AUTOSAR XML (schema 314)
package /ComponentType
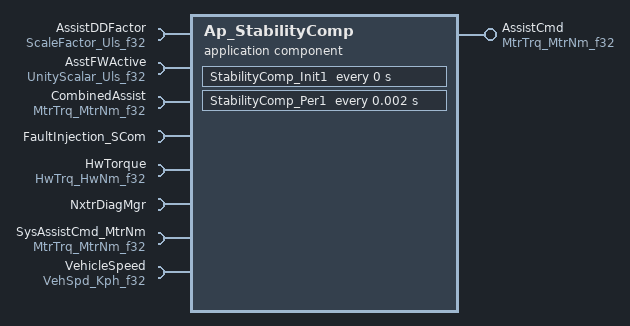
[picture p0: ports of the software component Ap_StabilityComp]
  application software component type Ap_StabilityComp
    provide port AssistCmd: unqueued-sender-com-spec{data-element=MtrNm_f32, can-invalidate=false, init-value=D_ZERO_ULS_F32}, provided-interface=MtrTrq_MtrNm_f32
    8 x require port:
      AssistDDFactor: unqueued-receiver-com-spec{data-element=Uls_f32, init-value=D_ONE_ULS_F32}, required-interface=ScaleFactor_Uls_f32
      AsstFWActive: unqueued-receiver-com-spec{data-element=Uls_f32, init-value=D_ZERO_ULS_F32}, required-interface=UnityScalar_Uls_f32
      CombinedAssist: unqueued-receiver-com-spec{data-element=MtrNm_f32, init-value=D_ZERO_ULS_F32}, required-interface=MtrTrq_MtrNm_f32
      FaultInjection_SCom: client-com-spec=FltInjection, required-interface=FaultInjection_SCom
      HwTorque: unqueued-receiver-com-spec{data-element=HwNm_f32, init-value=D_ZERO_ULS_F32}, required-interface=HwTrq_HwNm_f32
      NxtrDiagMgr: required-com-specs=[GetNTCActive, GetNTCFailed, GetNTCStatus, SetNTCStatus], required-interface=NxtrDiagMgr
      SysAssistCmd_MtrNm: unqueued-receiver-com-spec{data-element=MtrNm_f32, init-value=D_ZERO_ULS_F32}, required-interface=MtrTrq_MtrNm_f32
      VehicleSpeed: unqueued-receiver-com-spec{data-element=Kph_f32, init-value=D_ZERO_ULS_F32}, required-interface=VehSpd_Kph_f32
  internal behavior Ap_StabilityComp_InternalBehavior: component=Ap_StabilityComp
    timing event StabilityComp_Init1_InitEvent: start-on-event=StabilityComp_Init1, period=0
    timing event TMT_StabilityComp_Per1: start-on-event=StabilityComp_Per1, period=0.002
    port-api-options:
      enable-take-address=false, indirect-api=false, port=AssistCmd
      enable-take-address=false, indirect-api=false, port=AssistDDFactor
      enable-take-address=false, indirect-api=false, port=AsstFWActive
      enable-take-address=false, indirect-api=false, port=CombinedAssist
      enable-take-address=false, indirect-api=false, port=FaultInjection_SCom
      enable-take-address=false, indirect-api=false, port=HwTorque
      enable-take-address=false, indirect-api=false, port=NxtrDiagMgr
      enable-take-address=false, indirect-api=false, port=SysAssistCmd_MtrNm
      enable-take-address=false, indirect-api=false, port=VehicleSpeed
    runnable StabilityComp_Init1
    runnable StabilityComp_Per1
      6 x data read access:
        READ_AssistDDFactor_Uls_f32: data-element=AssistDDFactor.Uls_f32
        READ_AsstFWActive_Uls_f32: data-element=AsstFWActive.Uls_f32
        READ_CombinedAssist_MtrNm_f32: data-element=CombinedAssist.MtrNm_f32
        READ_HwTorque_HwNm_f32: data-element=HwTorque.HwNm_f32
        READ_SysAssistCmd_MtrNm_MtrNm_f32: data-element=SysAssistCmd_MtrNm.MtrNm_f32
        READ_VehicleSpeed_Kph_f32: data-element=VehicleSpeed.Kph_f32
      data write access WRITE_AssistCmd_MtrNm_f32: data-element=AssistCmd.MtrNm_f32
      sync call SC_FaultInjection_SCom_FltInjection: operation=FaultInjection_SCom.FltInjection, timeout=0
      sync call SC_NxtrDiagMgr_SetNTCStatus: operation=NxtrDiagMgr.SetNTCStatus, timeout=0
  swc implementation Ap_StabilityComp_Implementation: behavior=Ap_StabilityComp_InternalBehavior
    code-descriptors:
      code Code: type=SRC
